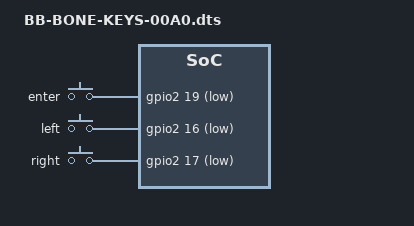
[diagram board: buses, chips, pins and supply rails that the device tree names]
/**
 * @file
 * @brief Device Tree Overlay to configure GPIOs as /dev/event inputs
 *
 * @author Troy Dack
 * @date Copyright (C) 2015
 *
 * This program is free software; you can redistribute it and/or modify
 * it under the terms of the GNU General Public License as published by
 * the Free Software Foundation; either version 2 of the License, or
 * (at your option) any later version.
 *
 * This program is distributed in the hope that it will be useful,
 * but WITHOUT ANY WARRANTY; without even the implied warranty of
 * MERCHANTABILITY or FITNESS FOR A PARTICULAR PURPOSE.  See the
 * GNU General Public License for more details.
 *
 * You should have received a copy of the GNU General Public License along
 * with this program; if not, write to the Free Software Foundation, Inc.,
 * 51 Franklin Street, Fifth Floor, Boston, MA 02110-1301 USA.
 *
 **/

/dts-v1/;
/plugin/;

/{
	compatible = "ti,beaglebone-black";
	
	/* identification */
	part-number = "BB-BONE-KEYS";
	version = "00A0";

	fragment@0 {
		target = <&am33xx_pinmux>;
		__overlay__ {
			pushbutton_pins: pinmux_pushbutton_pins {
				pinctrl-single,pins = <
					0x04c 0x37 // P9_16 pull-up mode 7 GPIO1_28
					0x040 0x37 // P9_15 pull-up mode 7 GPIO1_16
					0x044 0x37 // P9_23 pull-up mode 7 GPIO1_17
				>;
			};
		};
	};
	
	fragment@1 {
		target = <&ocp>;
		__overlay__ {
			/* avoid warnings */
			#address-cells = <1>;
			#size-cells	= <1>;
			
			gpio_keys {
				compatible = "gpio-keys";
				pinctrl-names = "default";
				pinctrl-0 = <&pushbutton_pins>;
				#address-cells = <1>;
				#size-cells	= <0>;
				
				button@1 {
					debounce_interval = <50>;
					linux,code = <28>;
					label = "enter";
					gpios = <&gpio2 19 0x1>;
					gpio-key,wakeup;
					autorepeat;
				};
				button@2 {
					debounce_interval = <50>;
					linux,code = <105>;
					label = "left";
					gpios = <&gpio2 16 0x1>;
					gpio-key,wakeup;
					autorepeat;
				};
				button@3 {
					debounce_interval = <50>;
					linux,code = <106>;
					label = "right";
					gpios = <&gpio2 17 0x1>;
					gpio-key,wakeup;
					autorepeat;
				};
			};
		};
	};
};
